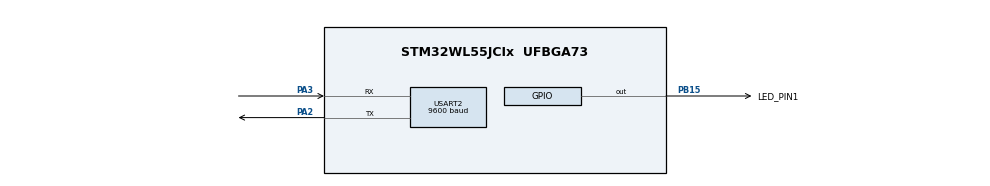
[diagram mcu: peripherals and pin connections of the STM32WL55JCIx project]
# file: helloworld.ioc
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Dma.Request0=USART2_RX
Dma.USART2_RX.0.Channel_PRIV_NPRIV=DMA_CHANNEL_NPRIV_DISABLE
Dma.USART2_RX.0.Direction=DMA_PERIPH_TO_MEMORY
Dma.USART2_RX.0.EventEnable=DISABLE
Dma.USART2_RX.0.Instance=DMA1_Channel1
Dma.USART2_RX.0.MemDataAlignment=DMA_MDATAALIGN_BYTE
Dma.USART2_RX.0.MemInc=DMA_MINC_ENABLE
Dma.USART2_RX.0.Mode=DMA_CIRCULAR
Dma.USART2_RX.0.PeriphDataAlignment=DMA_PDATAALIGN_BYTE
Dma.USART2_RX.0.PeriphInc=DMA_PINC_DISABLE
Dma.USART2_RX.0.Polarity=HAL_DMAMUX_REQ_GEN_RISING
Dma.USART2_RX.0.Priority=DMA_PRIORITY_LOW
Dma.USART2_RX.0.RequestNumber=1
Dma.USART2_RX.0.SignalID=NONE
Dma.USART2_RX.0.SyncEnable=DISABLE
Dma.USART2_RX.0.SyncPolarity=HAL_DMAMUX_SYNC_NO_EVENT
Dma.USART2_RX.0.SyncRequestNumber=1
Dma.USART2_RX.0.SyncSignalID=NONE
Mcu.Family=STM32WL
Mcu.Name=STM32WL55JCIx
Mcu.Package=UFBGA73
NVIC.DMA1_Channel1_IRQn=true\:2\:0\:true\:false\:true\:false\:true\:true
NVIC.PriorityGroup=NVIC_PRIORITYGROUP_4
OSC_IN.Mode=HSE-External-Oscillator
OSC_IN.Signal=RCC_OSC_IN
OSC_OUT.Mode=HSE-External-Oscillator
OSC_OUT.Signal=RCC_OSC_OUT
PA2.Mode=Asynchronous
PA2.Signal=USART2_TX
PA3.Mode=Asynchronous
PA3.Signal=USART2_RX
PB15.GPIO_Label=LED_PIN1
PB15.Signal=GPIO_Output
ProjectManager.HeapSize=0x200
ProjectManager.StackSize=0x400
ProjectManager.TargetToolchain=STM32CubeIDE
RCC.HSE_VALUE=8000000
RCC.HSI_VALUE=16000000
RCC.LSE_VALUE=32768
RCC.VCOOutputFreq_Value=32000000
USART2.BaudRate=9600
USART2.VirtualMode-Asynchronous=VM_ASYNC
board=custom

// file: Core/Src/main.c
/* USER CODE BEGIN Header
 *
 *   * TC-19: Verificar as tensões de operação nos I/O's digitais
  *  ->Input: usar um potenciômetro para variar a tensão do sinal sendo aplicado no pino de entrada.
  *  	1. Teste de tensões máximas e mínimas para os níveis lógicos (HIGH e LOW)
  *
  *  ->Output: medir a tensão gerada no pino nos níveis lógicos HIGH e LOW.
  *  	1.Teste em quantidade - Mede em LOW, ativa, mede em HIGH, desliga. (10x por teste)
  *  	2.Teste em stress - Medição contínua em estado HIGH do pino.
 *
 *  */
/**
  ******************************************************************************
  * @file           : main.c
  * @brief          : Main program body
  ******************************************************************************
  * @attention
  *
  * Copyright (c) 2023 STMicroelectronics.
  * All rights reserved.
  *
  * This software is licensed under terms that can be found in the LICENSE file
  * in the root directory of this software component.
  * If no LICENSE file comes with this software, it is provided AS-IS.
  *
  ******************************************************************************
  */
/* USER CODE END Header */
#include "main.h"

UART_HandleTypeDef huart2;
DMA_HandleTypeDef hdma_usart2_rx;

/* USER CODE BEGIN PV */
uint8_t txdata[50] = "Hello World! Essa é sua mensagem:\n\r";
uint8_t rxdata[10];
uint16_t Time = 600;
/* USER CODE END PV */

void SystemClock_Config(void);
static void MX_GPIO_Init(void);
static void MX_DMA_Init(void);
static void MX_USART2_UART_Init(void);

int main(void)
{

  /* MCU Configuration--------------------------------------------------------*/

  /* Reset of all peripherals, Initializes the Flash interface and the Systick. */
  HAL_Init();

  /* Configure the system clock */
  SystemClock_Config();

  /* Initialize all configured peripherals */
  MX_GPIO_Init();
  MX_DMA_Init();
  MX_USART2_UART_Init();
  /* USER CODE BEGIN 2 */
  HAL_UART_Receive_DMA(&huart2, rxdata, sizeof(rxdata));

  /* USER CODE END 2 */

  /* Infinite loop */
  /* USER CODE BEGIN WHILE */
  while (1)
  {

	  //HAL_UART_Receive_IT(&huart2, rxdata, sizeof(rxdata));
	  /*HAL_UART_Receive(&huart2, rxdata, sizeof(rxdata),200);
	  HAL_UART_Transmit(&huart2, rxdata, sizeof(rxdata),200);*/
//	  HAL_GPIO_TogglePin(LED_PIN1_GPIO_Port, LED_PIN1_Pin);
//	  HAL_Delay(300);

    /* USER CODE END WHILE */

  }
}

void SystemClock_Config(void)
{
  RCC_OscInitTypeDef RCC_OscInitStruct = {0};
  RCC_ClkInitTypeDef RCC_ClkInitStruct = {0};

  /** Configure the main internal regulator output voltage
  */
  __HAL_PWR_VOLTAGESCALING_CONFIG(PWR_REGULATOR_VOLTAGE_SCALE2);

  /** Initializes the CPU, AHB and APB buses clocks
  */
  RCC_OscInitStruct.OscillatorType = RCC_OSCILLATORTYPE_MSI;
  RCC_OscInitStruct.MSIState = RCC_MSI_ON;
  RCC_OscInitStruct.MSICalibrationValue = RCC_MSICALIBRATION_DEFAULT;
  RCC_OscInitStruct.MSIClockRange = RCC_MSIRANGE_6;
  RCC_OscInitStruct.PLL.PLLState = RCC_PLL_NONE;
  if (HAL_RCC_OscConfig(&RCC_OscInitStruct) != HAL_OK)
  {
    Error_Handler();
  }

  /** Configure the SYSCLKSource, HCLK, PCLK1 and PCLK2 clocks dividers
  */
  RCC_ClkInitStruct.ClockType = RCC_CLOCKTYPE_HCLK3|RCC_CLOCKTYPE_HCLK
                              |RCC_CLOCKTYPE_SYSCLK|RCC_CLOCKTYPE_PCLK1
                              |RCC_CLOCKTYPE_PCLK2;
  RCC_ClkInitStruct.SYSCLKSource = RCC_SYSCLKSOURCE_MSI;
  RCC_ClkInitStruct.AHBCLKDivider = RCC_SYSCLK_DIV1;
  RCC_ClkInitStruct.APB1CLKDivider = RCC_HCLK_DIV1;
  RCC_ClkInitStruct.APB2CLKDivider = RCC_HCLK_DIV1;
  RCC_ClkInitStruct.AHBCLK3Divider = RCC_SYSCLK_DIV1;

  if (HAL_RCC_ClockConfig(&RCC_ClkInitStruct, FLASH_LATENCY_0) != HAL_OK)
  {
    Error_Handler();
  }
}

static void MX_USART2_UART_Init(void)
{

  huart2.Instance = USART2;
  huart2.Init.BaudRate = 9600;
  huart2.Init.WordLength = UART_WORDLENGTH_8B;
  huart2.Init.StopBits = UART_STOPBITS_1;
  huart2.Init.Parity = UART_PARITY_NONE;
  huart2.Init.Mode = UART_MODE_TX_RX;
  huart2.Init.HwFlowCtl = UART_HWCONTROL_NONE;
  huart2.Init.OverSampling = UART_OVERSAMPLING_16;
  huart2.Init.OneBitSampling = UART_ONE_BIT_SAMPLE_DISABLE;
  huart2.Init.ClockPrescaler = UART_PRESCALER_DIV1;
  huart2.AdvancedInit.AdvFeatureInit = UART_ADVFEATURE_NO_INIT;
  if (HAL_UART_Init(&huart2) != HAL_OK)
  {
    Error_Handler();
  }
  if (HAL_UARTEx_SetTxFifoThreshold(&huart2, UART_TXFIFO_THRESHOLD_1_8) != HAL_OK)
  {
    Error_Handler();
  }
  if (HAL_UARTEx_SetRxFifoThreshold(&huart2, UART_RXFIFO_THRESHOLD_1_8) != HAL_OK)
  {
    Error_Handler();
  }
  if (HAL_UARTEx_DisableFifoMode(&huart2) != HAL_OK)
  {
    Error_Handler();
  }

}

static void MX_DMA_Init(void)
{

  /* DMA controller clock enable */
  __HAL_RCC_DMAMUX1_CLK_ENABLE();
  __HAL_RCC_DMA1_CLK_ENABLE();

  /* DMA interrupt init */
  /* DMA1_Channel1_IRQn interrupt configuration */
  HAL_NVIC_SetPriority(DMA1_Channel1_IRQn, 2, 0);
  HAL_NVIC_EnableIRQ(DMA1_Channel1_IRQn);

}

static void MX_GPIO_Init(void)
{
  GPIO_InitTypeDef GPIO_InitStruct = {0};

  /* GPIO Ports Clock Enable */
  __HAL_RCC_GPIOB_CLK_ENABLE();
  __HAL_RCC_GPIOA_CLK_ENABLE();

  /*Configure GPIO pin Output Level */
  HAL_GPIO_WritePin(LED_PIN1_GPIO_Port, LED_PIN1_Pin, GPIO_PIN_RESET);

  /*Configure GPIO pin : LED_PIN1_Pin */
  GPIO_InitStruct.Pin = LED_PIN1_Pin;
  GPIO_InitStruct.Mode = GPIO_MODE_OUTPUT_PP;
  GPIO_InitStruct.Pull = GPIO_NOPULL;
  GPIO_InitStruct.Speed = GPIO_SPEED_FREQ_LOW;
  HAL_GPIO_Init(LED_PIN1_GPIO_Port, &GPIO_InitStruct);

}

/* USER CODE BEGIN 4 */

/**
  * @brief  This function is executed in case of error occurrence.
  * @retval None
  */

void HAL_UART_RxCpltCallback(UART_HandleTypeDef *huart)
{
	HAL_UART_Transmit(&huart2, rxdata, sizeof(rxdata),200);
	HAL_GPIO_TogglePin(LED_PIN1_GPIO_Port, LED_PIN1_Pin);
	HAL_Delay(300);
	HAL_GPIO_TogglePin(LED_PIN1_GPIO_Port, LED_PIN1_Pin);
}

/* USER CODE END 4 */

void Error_Handler(void)
{
  __disable_irq();
  while (1)
  {
  }
}
